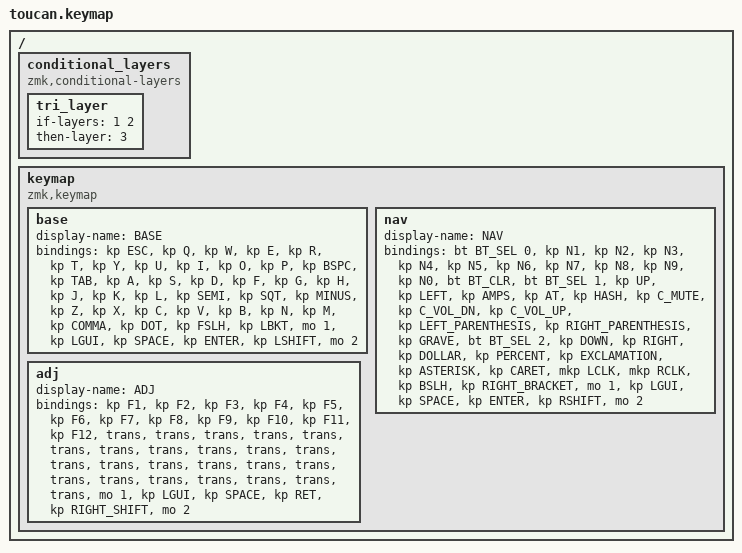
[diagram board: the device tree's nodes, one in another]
#include <behaviors.dtsi>
#include <dt-bindings/zmk/bt.h>
#include <dt-bindings/zmk/keys.h>
#include <dt-bindings/zmk/pointing.h>

#define BASE 0
#define NAV  1
#define SYM  2
#define ADJ  3

/ {
    conditional_layers {
        compatible = "zmk,conditional-layers";

        tri_layer {
            if-layers = <1 2>;
            then-layer = <3>;
        };
    };

    keymap {
        compatible = "zmk,keymap";

        base {
            display-name = "BASE";
            bindings = <
&kp ESC  &kp Q  &kp W  &kp E  &kp R  &kp T  &kp Y  &kp U  &kp I  &kp O  &kp P  &kp BSPC  &kp TAB  &kp A  &kp S  &kp D  &kp F  &kp G  &kp H  &kp J  &kp K  &kp L  &kp SEMI  &kp SQT  &kp MINUS  &kp Z  &kp X  &kp C  &kp V  &kp B  &kp N  &kp M  &kp COMMA  &kp DOT  &kp FSLH  &kp LBKT  &mo 1  &kp LGUI  &kp SPACE  &kp ENTER  &kp LSHIFT  &mo 2
            >;
        };

        nav {
            display-name = "NAV";
            bindings = <
&bt BT_SEL 0  &kp N1  &kp N2  &kp N3  &kp N4  &kp N5  &kp N6  &kp N7  &kp N8  &kp N9  &kp N0  &bt BT_CLR  &bt BT_SEL 1  &kp UP  &kp LEFT  &kp AMPS  &kp AT  &kp HASH  &kp C_MUTE  &kp C_VOL_DN  &kp C_VOL_UP  &kp LEFT_PARENTHESIS  &kp RIGHT_PARENTHESIS  &kp GRAVE  &bt BT_SEL 2  &kp DOWN  &kp RIGHT  &kp DOLLAR  &kp PERCENT  &kp EXCLAMATION  &kp ASTERISK  &kp CARET  &mkp LCLK  &mkp RCLK  &kp BSLH  &kp RIGHT_BRACKET  &mo 1  &kp LGUI  &kp SPACE  &kp ENTER  &kp RSHIFT  &mo 2
            >;
        };

        adj {
            display-name = "ADJ";
            bindings = <
&kp F1  &kp F2  &kp F3  &kp F4  &kp F5  &kp F6  &kp F7  &kp F8  &kp F9  &kp F10  &kp F11  &kp F12  &trans  &trans  &trans  &trans  &trans  &trans  &trans  &trans  &trans  &trans  &trans  &trans  &trans  &trans  &trans  &trans  &trans  &trans  &trans  &trans  &trans  &trans  &trans  &trans  &mo 1  &kp LGUI  &kp SPACE  &kp RET  &kp RIGHT_SHIFT  &mo 2
            >;
        };
    };
};
